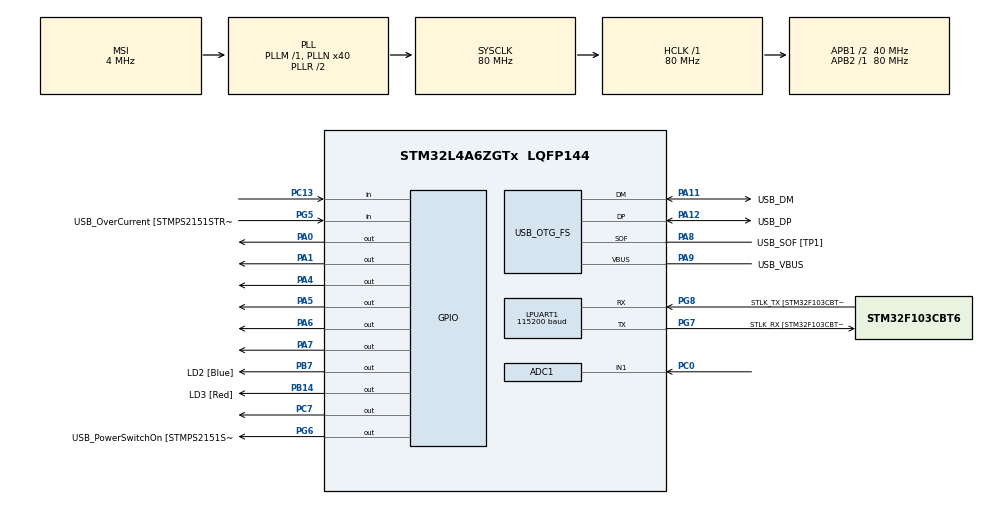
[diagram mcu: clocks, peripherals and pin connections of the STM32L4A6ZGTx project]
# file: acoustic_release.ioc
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ADC1.Channel-1\#ChannelRegularConversion=ADC_CHANNEL_1
ADC1.ContinuousConvMode=ENABLE
ADC1.DMAContinuousRequests=ENABLE
ADC1.ExternalTrigConv=ADC_SOFTWARE_START
ADC1.NbrOfConversion=1
ADC1.NbrOfConversionFlag=1
ADC1.OffsetNumber-1\#ChannelRegularConversion=ADC_OFFSET_NONE
ADC1.Rank-1\#ChannelRegularConversion=1
ADC1.SamplingTime-1\#ChannelRegularConversion=ADC_SAMPLETIME_47CYCLES_5
ADC1.master=1
Dma.ADC1.0.Direction=DMA_PERIPH_TO_MEMORY
Dma.ADC1.0.Instance=DMA1_Channel1
Dma.ADC1.0.MemDataAlignment=DMA_MDATAALIGN_HALFWORD
Dma.ADC1.0.MemInc=DMA_MINC_ENABLE
Dma.ADC1.0.Mode=DMA_NORMAL
Dma.ADC1.0.PeriphDataAlignment=DMA_PDATAALIGN_HALFWORD
Dma.ADC1.0.PeriphInc=DMA_PINC_DISABLE
Dma.ADC1.0.Priority=DMA_PRIORITY_VERY_HIGH
Dma.Request0=ADC1
LPUART1.AutoBaudRateEnableParam=UART_ADVFEATURE_AUTOBAUDRATE_DISABLE
LPUART1.BaudRate=115200
LPUART1.DMADisableonRxErrorParam=UART_ADVFEATURE_DMA_ENABLEONRXERROR
LPUART1.DataInvertParam=UART_ADVFEATURE_DATAINV_DISABLE
LPUART1.MSBFirstParam=UART_ADVFEATURE_MSBFIRST_DISABLE
LPUART1.Mode=UART_MODE_TX_RX
LPUART1.OneBitSampling=UART_ONE_BIT_SAMPLE_DISABLE
LPUART1.OverrunDisableParam=UART_ADVFEATURE_OVERRUN_ENABLE
LPUART1.Parity=UART_PARITY_NONE
LPUART1.RxPinLevelInvertParam=UART_ADVFEATURE_RXINV_DISABLE
LPUART1.StopBits=UART_STOPBITS_1
LPUART1.SwapParam=UART_ADVFEATURE_SWAP_DISABLE
LPUART1.TxPinLevelInvertParam=UART_ADVFEATURE_TXINV_DISABLE
LPUART1.WordLength=UART_WORDLENGTH_8B
Mcu.Family=STM32L4
Mcu.Name=STM32L4A6ZGTx
Mcu.Package=LQFP144
NVIC.DMA1_Channel1_IRQn=true\:0\:0\:false\:false\:true\:false\:true\:true
NVIC.PriorityGroup=NVIC_PRIORITYGROUP_4
PA0.GPIO_PuPd=GPIO_PULLDOWN
PA0.Signal=GPIO_Output
PA1.GPIO_PuPd=GPIO_PULLDOWN
PA1.Signal=GPIO_Output
PA10.GPIO_Label=USB_ID
PA10.Signal=USB_OTG_FS_ID
PA11.GPIO_Label=USB_DM
PA11.Mode=Device_Only
PA11.Signal=USB_OTG_FS_DM
PA12.GPIO_Label=USB_DP
PA12.Mode=Device_Only
PA12.Signal=USB_OTG_FS_DP
PA13\ (JTMS/SWDIO).GPIO_Label=TMS
PA13\ (JTMS/SWDIO).Mode=Trace_Asynchronous_SW
PA13\ (JTMS/SWDIO).Signal=SYS_JTMS-SWDIO
PA14\ (JTCK/SWCLK).GPIO_Label=TCK
PA14\ (JTCK/SWCLK).Mode=Trace_Asynchronous_SW
PA14\ (JTCK/SWCLK).Signal=SYS_JTCK-SWCLK
PA4.GPIO_PuPd=GPIO_PULLDOWN
PA4.Signal=GPIO_Output
PA5.GPIO_PuPd=GPIO_PULLDOWN
PA5.Signal=GPIO_Output
PA6.GPIO_PuPd=GPIO_PULLDOWN
PA6.Signal=GPIO_Output
PA7.GPIO_PuPd=GPIO_PULLDOWN
PA7.Signal=GPIO_Output
PA8.GPIO_Label=USB_SOF [TP1]
PA8.Mode=Activate_SOF_FS
PA8.Signal=USB_OTG_FS_SOF
PA9.GPIO_Label=USB_VBUS
PA9.Mode=Activate_VBUS
PA9.Signal=USB_OTG_FS_VBUS
PB14.GPIO_Label=LD3 [Red]
PB14.Signal=GPIO_Output
PB3\ (JTDO/TRACESWO).GPIO_Label=SWO
PB3\ (JTDO/TRACESWO).Mode=Trace_Asynchronous_SW
PB3\ (JTDO/TRACESWO).Signal=SYS_JTDO-SWO
PB7.GPIO_Label=LD2 [Blue]
PB7.Signal=GPIO_Output
PC0.Signal=ADCx_IN1
PC13.GPIO_PuPd=GPIO_PULLUP
PC13.Signal=GPIO_Input
PC14-OSC32_IN\ (PC14).Mode=LSE-External-Oscillator
PC14-OSC32_IN\ (PC14).Signal=RCC_OSC32_IN
PC15-OSC32_OUT\ (PC15).Mode=LSE-External-Oscillator
PC15-OSC32_OUT\ (PC15).Signal=RCC_OSC32_OUT
PC7.Signal=GPIO_Output
PG5.GPIO_Label=USB_OverCurrent [STMPS2151STR_FAULT]
PG5.Signal=GPIO_Input
PG6.GPIO_Label=USB_PowerSwitchOn [STMPS2151STR_EN]
PG6.Signal=GPIO_Output
PG7.GPIO_Label=STLK_RX [STM32F103CBT6_PA3]
PG7.Mode=Asynchronous
PG7.Signal=LPUART1_TX
PG8.GPIO_Label=STLK_TX [STM32F103CBT6_PA2]
PG8.Mode=Asynchronous
PG8.Signal=LPUART1_RX
PH1-OSC_OUT\ (PH1).Signal=RCC_OSC_OUT
ProjectManager.HeapSize=0x200
ProjectManager.StackSize=0x400
ProjectManager.TargetToolchain=STM32CubeIDE
RCC.ADCCLockSelection=RCC_ADCCLKSOURCE_PLLSAI2
RCC.ADCFreq_Value=30000000
RCC.AHBFreq_Value=80000000
RCC.APB1CLKDivider=RCC_HCLK_DIV2
RCC.APB1Freq_Value=40000000
RCC.APB1TimFreq_Value=80000000
RCC.APB2Freq_Value=80000000
RCC.APB2TimFreq_Value=80000000
RCC.CortexFreq_Value=80000000
RCC.FLatency=FLASH_LATENCY_4
RCC.HCLKFreq_Value=80000000
RCC.HSE_VALUE=8000000
RCC.HSI48_VALUE=48000000
RCC.HSI_VALUE=16000000
RCC.MSI_VALUE=4000000
RCC.PLLN=40
RCC.PLLSAI1N=24
RCC.PLLSAI2N=30
RCC.PLLSAI2R=RCC_PLLR_DIV4
RCC.SYSCLKFreq_VALUE=80000000
RCC.SYSCLKSource=RCC_SYSCLKSOURCE_PLLCLK
RCC.USBFreq_Value=48000000
RCC.VCOOutputFreq_Value=160000000
SH.ADCx_IN1.0=ADC1_IN1,IN1-Single-Ended
USB_OTG_FS.Sof_enable=ENABLE
USB_OTG_FS.VirtualMode=Device_Only
USB_OTG_FS.battery_charging_enable=ENABLE
USB_OTG_FS.low_power_enable=DISABLE
USB_OTG_FS.lpm_enable=DISABLE
USB_OTG_FS.use_dedicated_ep1=DISABLE
USB_OTG_FS.vbus_sensing_enable=ENABLE
board=NUCLEO-L4A6ZG

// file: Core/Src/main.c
/* USER CODE BEGIN Header */
/**
 ******************************************************************************
 * @file           : main.c
 * @brief          : Main program body
 ******************************************************************************
 * @attention
 *
 * Copyright (c) 2022 STMicroelectronics.
 * All rights reserved.
 *
 * This software is licensed under terms that can be found in the LICENSE file
 * in the root directory of this software component.
 * If no LICENSE file comes with this software, it is provided AS-IS.
 *
 ******************************************************************************
 */
/* USER CODE END Header */
#include "main.h"

/* USER CODE BEGIN Includes */
#include "uart.h"
#include "sigdet.h"
#include "dcollect.h"
#include "settings.h"
#include "power.h"
/* USER CODE END Includes */

/* USER CODE BEGIN PD */
#define FFT_LEN 1024
/* USER CODE END PD */

ADC_HandleTypeDef hadc1;
DMA_HandleTypeDef hdma_adc1;

UART_HandleTypeDef hlpuart1;

PCD_HandleTypeDef hpcd_USB_OTG_FS;

/* USER CODE BEGIN PV */
uint16_t buf[FFT_LEN];
uint16_t imag[FFT_LEN];
uint16_t mag[FFT_LEN];
uint8_t adcbuf_ready = 0;
/* USER CODE END PV */

void SystemClock_Config(void);
static void MX_GPIO_Init(void);
static void MX_LPUART1_UART_Init(void);
static void MX_DMA_Init(void);
static void MX_ADC1_Init(void);
static void MX_USB_OTG_FS_PCD_Init(void);
/* USER CODE BEGIN PFP */
void dma_xfer_cplt(DMA_HandleTypeDef *hdma);
/* USER CODE END PFP */

int main(void)
{
  /* Reset of all peripherals, Initializes the Flash interface and the Systick. */
  HAL_Init();

  /* Configure the system clock */
  SystemClock_Config();

  /* Initialize all configured peripherals */
  MX_GPIO_Init();
  MX_LPUART1_UART_Init();
  MX_DMA_Init();
  MX_ADC1_Init();
  MX_USB_OTG_FS_PCD_Init();
  /* USER CODE BEGIN 2 */

    /* Enable transmitter */
    LPUART1->CR1 |= 1 << 3;
    int i = 0;
    uint8_t foundf1, foundf2, release;

    // clear GPIO B7 - this is the release LED
    HAL_GPIO_WritePin(GPIOB, GPIO_PIN_7, GPIO_PIN_RESET);

    // macros -> set input bits in DEV_GPIO_PORT
    POWER_ON(PREAMP); // pin 7
    POWER_ON(FILTER); // pin 6

    HAL_Delay(1000);

    //enable ADC peripheral on hadc1 with buf as buffer with length FFT_LEN
    HAL_ADC_Start_DMA(&hadc1, (uint32_t*)buf, FFT_LEN);

    while (1)
    {
    	// this flag starts at 0
        if (adcbuf_ready) {
            adcbuf_ready = 0;
            /* Send data over UART if DEBUG mode is active. Can change this in settings.h */
#ifdef DEBUG
            send_ss_seq();
#endif
            // buf = real array
            // imag = imaginary array
            // m (10) sets sample frequency, 1 << m (10) counts
            // 0 = forward transform, 1 = imaginary transform

            // scale FFT array to prevent overflow
            fix_fft(buf, imag, 10, 0);

            // populate mag array with detected magnitudes from FFT
            compute_freq_mag(buf, imag, mag, 0, FFT_LEN);

            // determine if low frequency is found
            foundf1 = sigdet(buf, imag, mag, FREQL);

            // determine if high frequency is found
            foundf2 = sigdet(buf, imag, mag, FREQH);

            /* LEDs for visualizing what is being detected */
            if (foundf1)
                HAL_GPIO_WritePin(GPIOB, GPIO_PIN_14, GPIO_PIN_SET);
            else
                HAL_GPIO_WritePin(GPIOB, GPIO_PIN_14, GPIO_PIN_RESET);
            if (foundf2)
                HAL_GPIO_WritePin(GPIOC, GPIO_PIN_7, GPIO_PIN_SET);
            else
                HAL_GPIO_WritePin(GPIOC, GPIO_PIN_7, GPIO_PIN_RESET);

            /* Update state machine */
            release = check_state(foundf1, foundf2); // set if pattern found
            if (release) {
            	/* LED for visualization */
                HAL_GPIO_WritePin(GPIOB, GPIO_PIN_7, GPIO_PIN_SET);
                /* TODO: Activate servo */
            }

            // update UART on detected frequencies
#ifdef DEBUG
            send_samples(mag);
            send_ss_seq();
#endif
            // fill up new ADC sample reading
            HAL_ADC_Start_DMA(&hadc1, (uint32_t*)buf, FFT_LEN);
        }
    }
    /* USER CODE END WHILE */

}

void SystemClock_Config(void)
{
  RCC_OscInitTypeDef RCC_OscInitStruct = {0};
  RCC_ClkInitTypeDef RCC_ClkInitStruct = {0};

  /** Configure the main internal regulator output voltage
  */
  if (HAL_PWREx_ControlVoltageScaling(PWR_REGULATOR_VOLTAGE_SCALE1) != HAL_OK)
  {
    Error_Handler();
  }

  /** Configure LSE Drive Capability
  */
  HAL_PWR_EnableBkUpAccess();
  __HAL_RCC_LSEDRIVE_CONFIG(RCC_LSEDRIVE_LOW);

  /** Initializes the RCC Oscillators according to the specified parameters
  * in the RCC_OscInitTypeDef structure.
  */
  RCC_OscInitStruct.OscillatorType = RCC_OSCILLATORTYPE_LSE|RCC_OSCILLATORTYPE_MSI;
  RCC_OscInitStruct.LSEState = RCC_LSE_ON;
  RCC_OscInitStruct.MSIState = RCC_MSI_ON;
  RCC_OscInitStruct.MSICalibrationValue = 0;
  RCC_OscInitStruct.MSIClockRange = RCC_MSIRANGE_6;
  RCC_OscInitStruct.PLL.PLLState = RCC_PLL_ON;
  RCC_OscInitStruct.PLL.PLLSource = RCC_PLLSOURCE_MSI;
  RCC_OscInitStruct.PLL.PLLM = 1;
  RCC_OscInitStruct.PLL.PLLN = 40;
  RCC_OscInitStruct.PLL.PLLP = RCC_PLLP_DIV2;
  RCC_OscInitStruct.PLL.PLLQ = RCC_PLLQ_DIV2;
  RCC_OscInitStruct.PLL.PLLR = RCC_PLLR_DIV2;
  if (HAL_RCC_OscConfig(&RCC_OscInitStruct) != HAL_OK)
  {
    Error_Handler();
  }

  /** Initializes the CPU, AHB and APB buses clocks
  */
  RCC_ClkInitStruct.ClockType = RCC_CLOCKTYPE_HCLK|RCC_CLOCKTYPE_SYSCLK
                              |RCC_CLOCKTYPE_PCLK1|RCC_CLOCKTYPE_PCLK2;
  RCC_ClkInitStruct.SYSCLKSource = RCC_SYSCLKSOURCE_PLLCLK;
  RCC_ClkInitStruct.AHBCLKDivider = RCC_SYSCLK_DIV1;
  RCC_ClkInitStruct.APB1CLKDivider = RCC_HCLK_DIV2;
  RCC_ClkInitStruct.APB2CLKDivider = RCC_HCLK_DIV1;

  if (HAL_RCC_ClockConfig(&RCC_ClkInitStruct, FLASH_LATENCY_4) != HAL_OK)
  {
    Error_Handler();
  }

  /** Enable MSI Auto calibration
  */
  HAL_RCCEx_EnableMSIPLLMode();
}

static void MX_ADC1_Init(void)
{

  ADC_MultiModeTypeDef multimode = {0};
  ADC_ChannelConfTypeDef sConfig = {0};

  /** Common config
  */
  hadc1.Instance = ADC1;
  hadc1.Init.ClockPrescaler = ADC_CLOCK_ASYNC_DIV1;
  hadc1.Init.Resolution = ADC_RESOLUTION_12B;
  hadc1.Init.DataAlign = ADC_DATAALIGN_RIGHT;
  hadc1.Init.ScanConvMode = ADC_SCAN_DISABLE;
  hadc1.Init.EOCSelection = ADC_EOC_SINGLE_CONV;
  hadc1.Init.LowPowerAutoWait = DISABLE;
  hadc1.Init.ContinuousConvMode = ENABLE;
  hadc1.Init.NbrOfConversion = 1;
  hadc1.Init.DiscontinuousConvMode = DISABLE;
  hadc1.Init.ExternalTrigConv = ADC_SOFTWARE_START;
  hadc1.Init.ExternalTrigConvEdge = ADC_EXTERNALTRIGCONVEDGE_NONE;
  hadc1.Init.DMAContinuousRequests = ENABLE;
  hadc1.Init.Overrun = ADC_OVR_DATA_PRESERVED;
  hadc1.Init.OversamplingMode = DISABLE;
  if (HAL_ADC_Init(&hadc1) != HAL_OK)
  {
    Error_Handler();
  }

  /** Configure the ADC multi-mode
  */
  multimode.Mode = ADC_MODE_INDEPENDENT;
  if (HAL_ADCEx_MultiModeConfigChannel(&hadc1, &multimode) != HAL_OK)
  {
    Error_Handler();
  }

  /** Configure Regular Channel
  */
  sConfig.Channel = ADC_CHANNEL_1;
  sConfig.Rank = ADC_REGULAR_RANK_1;
  sConfig.SamplingTime = ADC_SAMPLETIME_47CYCLES_5;
  sConfig.SingleDiff = ADC_SINGLE_ENDED;
  sConfig.OffsetNumber = ADC_OFFSET_NONE;
  sConfig.Offset = 0;
  if (HAL_ADC_ConfigChannel(&hadc1, &sConfig) != HAL_OK)
  {
    Error_Handler();
  }

}

static void MX_LPUART1_UART_Init(void)
{

  hlpuart1.Instance = LPUART1;
  hlpuart1.Init.BaudRate = 115200;
  hlpuart1.Init.WordLength = UART_WORDLENGTH_8B;
  hlpuart1.Init.StopBits = UART_STOPBITS_1;
  hlpuart1.Init.Parity = UART_PARITY_NONE;
  hlpuart1.Init.Mode = UART_MODE_TX_RX;
  hlpuart1.Init.HwFlowCtl = UART_HWCONTROL_NONE;
  hlpuart1.Init.OneBitSampling = UART_ONE_BIT_SAMPLE_DISABLE;
  hlpuart1.AdvancedInit.AdvFeatureInit = UART_ADVFEATURE_NO_INIT;
  if (HAL_UART_Init(&hlpuart1) != HAL_OK)
  {
    Error_Handler();
  }

}

static void MX_USB_OTG_FS_PCD_Init(void)
{

  hpcd_USB_OTG_FS.Instance = USB_OTG_FS;
  hpcd_USB_OTG_FS.Init.dev_endpoints = 6;
  hpcd_USB_OTG_FS.Init.speed = PCD_SPEED_FULL;
  hpcd_USB_OTG_FS.Init.phy_itface = PCD_PHY_EMBEDDED;
  hpcd_USB_OTG_FS.Init.Sof_enable = ENABLE;
  hpcd_USB_OTG_FS.Init.low_power_enable = DISABLE;
  hpcd_USB_OTG_FS.Init.lpm_enable = DISABLE;
  hpcd_USB_OTG_FS.Init.battery_charging_enable = ENABLE;
  hpcd_USB_OTG_FS.Init.use_dedicated_ep1 = DISABLE;
  hpcd_USB_OTG_FS.Init.vbus_sensing_enable = ENABLE;
  if (HAL_PCD_Init(&hpcd_USB_OTG_FS) != HAL_OK)
  {
    Error_Handler();
  }

}

static void MX_DMA_Init(void)
{

  /* DMA controller clock enable */
  __HAL_RCC_DMA1_CLK_ENABLE();

  /* DMA interrupt init */
  /* DMA1_Channel1_IRQn interrupt configuration */
  HAL_NVIC_SetPriority(DMA1_Channel1_IRQn, 0, 0);
  HAL_NVIC_EnableIRQ(DMA1_Channel1_IRQn);

}

static void MX_GPIO_Init(void)
{
  GPIO_InitTypeDef GPIO_InitStruct = {0};

  /* GPIO Ports Clock Enable */
  __HAL_RCC_GPIOC_CLK_ENABLE();
  __HAL_RCC_GPIOH_CLK_ENABLE();
  __HAL_RCC_GPIOA_CLK_ENABLE();
  __HAL_RCC_GPIOB_CLK_ENABLE();
  __HAL_RCC_GPIOG_CLK_ENABLE();
  HAL_PWREx_EnableVddIO2();

  /*Configure GPIO pin Output Level */
  HAL_GPIO_WritePin(GPIOA, GPIO_PIN_0|GPIO_PIN_1|GPIO_PIN_4|GPIO_PIN_5
                          |GPIO_PIN_6|GPIO_PIN_7, GPIO_PIN_RESET);

  /*Configure GPIO pin Output Level */
  HAL_GPIO_WritePin(GPIOB, LD3_Pin|LD2_Pin, GPIO_PIN_RESET);

  /*Configure GPIO pin Output Level */
  HAL_GPIO_WritePin(USB_PowerSwitchOn_GPIO_Port, USB_PowerSwitchOn_Pin, GPIO_PIN_RESET);

  /*Configure GPIO pin Output Level */
  HAL_GPIO_WritePin(GPIOC, GPIO_PIN_7, GPIO_PIN_RESET);

  /*Configure GPIO pin : PC13 */
  GPIO_InitStruct.Pin = GPIO_PIN_13;
  GPIO_InitStruct.Mode = GPIO_MODE_INPUT;
  GPIO_InitStruct.Pull = GPIO_PULLUP;
  HAL_GPIO_Init(GPIOC, &GPIO_InitStruct);

  /*Configure GPIO pins : PA0 PA1 PA4 PA5
                           PA6 PA7 */
  GPIO_InitStruct.Pin = GPIO_PIN_0|GPIO_PIN_1|GPIO_PIN_4|GPIO_PIN_5
                          |GPIO_PIN_6|GPIO_PIN_7;
  GPIO_InitStruct.Mode = GPIO_MODE_OUTPUT_PP;
  GPIO_InitStruct.Pull = GPIO_PULLDOWN;
  GPIO_InitStruct.Speed = GPIO_SPEED_FREQ_LOW;
  HAL_GPIO_Init(GPIOA, &GPIO_InitStruct);

  /*Configure GPIO pins : LD3_Pin LD2_Pin */
  GPIO_InitStruct.Pin = LD3_Pin|LD2_Pin;
  GPIO_InitStruct.Mode = GPIO_MODE_OUTPUT_PP;
  GPIO_InitStruct.Pull = GPIO_NOPULL;
  GPIO_InitStruct.Speed = GPIO_SPEED_FREQ_LOW;
  HAL_GPIO_Init(GPIOB, &GPIO_InitStruct);

  /*Configure GPIO pin : USB_OverCurrent_Pin */
  GPIO_InitStruct.Pin = USB_OverCurrent_Pin;
  GPIO_InitStruct.Mode = GPIO_MODE_INPUT;
  GPIO_InitStruct.Pull = GPIO_NOPULL;
  HAL_GPIO_Init(USB_OverCurrent_GPIO_Port, &GPIO_InitStruct);

  /*Configure GPIO pin : USB_PowerSwitchOn_Pin */
  GPIO_InitStruct.Pin = USB_PowerSwitchOn_Pin;
  GPIO_InitStruct.Mode = GPIO_MODE_OUTPUT_PP;
  GPIO_InitStruct.Pull = GPIO_NOPULL;
  GPIO_InitStruct.Speed = GPIO_SPEED_FREQ_LOW;
  HAL_GPIO_Init(USB_PowerSwitchOn_GPIO_Port, &GPIO_InitStruct);

  /*Configure GPIO pin : PC7 */
  GPIO_InitStruct.Pin = GPIO_PIN_7;
  GPIO_InitStruct.Mode = GPIO_MODE_OUTPUT_PP;
  GPIO_InitStruct.Pull = GPIO_NOPULL;
  GPIO_InitStruct.Speed = GPIO_SPEED_FREQ_LOW;
  HAL_GPIO_Init(GPIOC, &GPIO_InitStruct);

}

/* USER CODE BEGIN 4 */
/* Interrupt called when DMA transfer is done -
 * set flag variable to start computation in main loop
 */
void HAL_ADC_ConvCpltCallback(ADC_HandleTypeDef *hadc) {
    HAL_ADC_Stop_DMA(&hadc1);
    adcbuf_ready = 1;
}
/* USER CODE END 4 */

void Error_Handler(void)
{
    __disable_irq();
    while (1)
    {
    }
}
